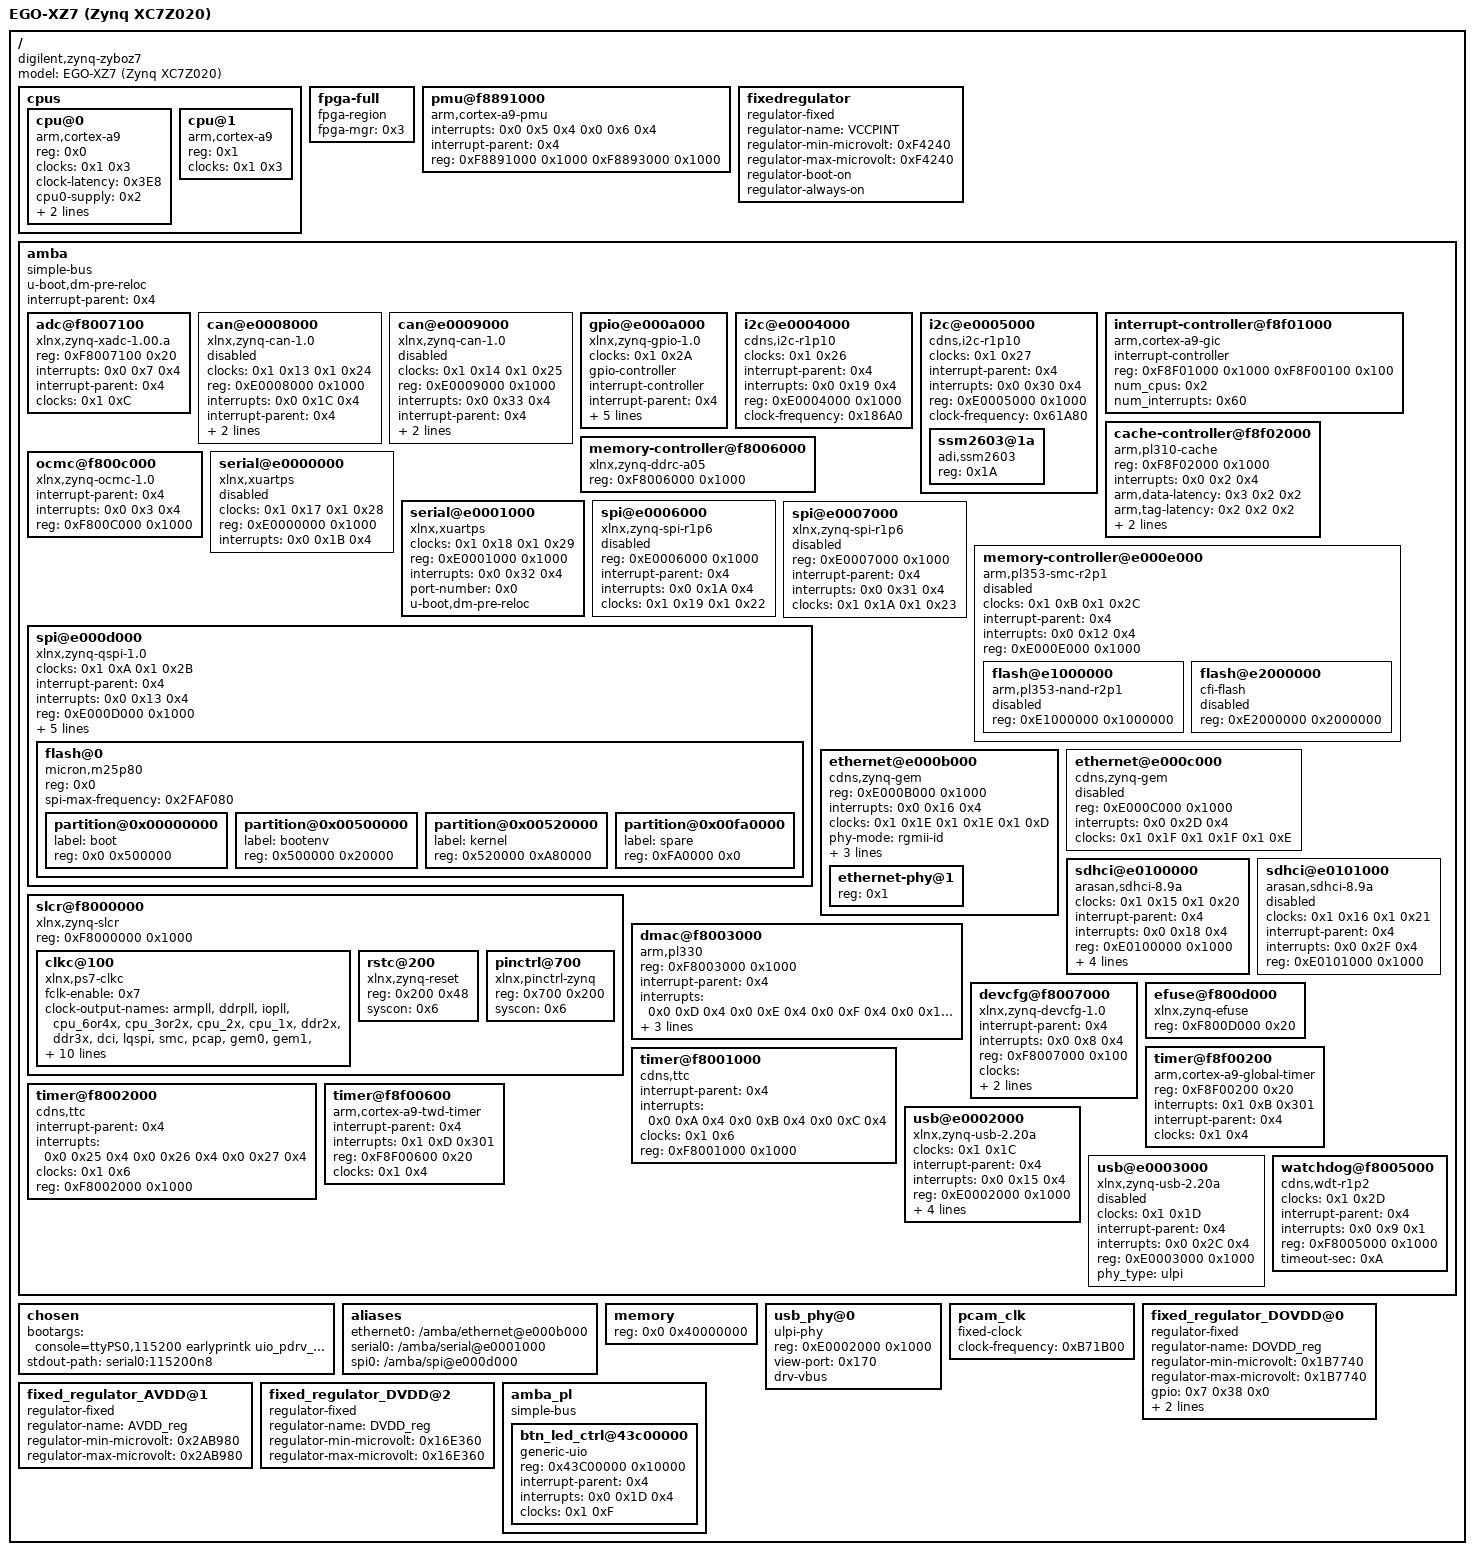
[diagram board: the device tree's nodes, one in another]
/dts-v1/;
// version: 17
// last_comp_version: 16
// boot_cpuid_phys: 0x0

/ {
    #address-cells = <0x1>;
    #size-cells = <0x1>;
    compatible = "digilent,zynq-zyboz7", "xlnx,zynq-7000";
    model = "EGO-XZ7 (Zynq XC7Z020)";
    cpus {
        #address-cells = <0x1>;
        #size-cells = <0x0>;
        cpu@0 {
            compatible = "arm,cortex-a9";
            device_type = "cpu";
            reg = <0x0>;
            clocks = <0x1 0x3>;
            clock-latency = <0x3E8>;
            cpu0-supply = <0x2>;
            operating-points = <0xA2C2A 0xF4240 0x51615 0xF4240>;
        };
        cpu@1 {
            compatible = "arm,cortex-a9";
            device_type = "cpu";
            reg = <0x1>;
            clocks = <0x1 0x3>;
        };
    };
    fpga-full {
        compatible = "fpga-region";
        fpga-mgr = <0x3>;
        #address-cells = <0x1>;
        #size-cells = <0x1>;
        ranges;
    };
    pmu@f8891000 {
        compatible = "arm,cortex-a9-pmu";
        interrupts = <0x0 0x5 0x4 0x0 0x6 0x4>;
        interrupt-parent = <0x4>;
        reg = <0xF8891000 0x1000 0xF8893000 0x1000>;
    };
    fixedregulator {
        compatible = "regulator-fixed";
        regulator-name = "VCCPINT";
        regulator-min-microvolt = <0xF4240>;
        regulator-max-microvolt = <0xF4240>;
        regulator-boot-on;
        regulator-always-on;
        linux,phandle = <0x2>;
        phandle = <0x2>;
    };
    amba {
        u-boot,dm-pre-reloc;
        compatible = "simple-bus";
        #address-cells = <0x1>;
        #size-cells = <0x1>;
        interrupt-parent = <0x4>;
        ranges;
        adc@f8007100 {
            compatible = "xlnx,zynq-xadc-1.00.a";
            reg = <0xF8007100 0x20>;
            interrupts = <0x0 0x7 0x4>;
            interrupt-parent = <0x4>;
            clocks = <0x1 0xC>;
        };
        can@e0008000 {
            compatible = "xlnx,zynq-can-1.0";
            status = "disabled";
            clocks = <0x1 0x13 0x1 0x24>;
            clock-names = "can_clk", "pclk";
            reg = <0xE0008000 0x1000>;
            interrupts = <0x0 0x1C 0x4>;
            interrupt-parent = <0x4>;
            tx-fifo-depth = <0x40>;
            rx-fifo-depth = <0x40>;
        };
        can@e0009000 {
            compatible = "xlnx,zynq-can-1.0";
            status = "disabled";
            clocks = <0x1 0x14 0x1 0x25>;
            clock-names = "can_clk", "pclk";
            reg = <0xE0009000 0x1000>;
            interrupts = <0x0 0x33 0x4>;
            interrupt-parent = <0x4>;
            tx-fifo-depth = <0x40>;
            rx-fifo-depth = <0x40>;
        };
        gpio@e000a000 {
            compatible = "xlnx,zynq-gpio-1.0";
            #gpio-cells = <0x2>;
            clocks = <0x1 0x2A>;
            gpio-controller;
            interrupt-controller;
            #interrupt-cells = <0x2>;
            interrupt-parent = <0x4>;
            interrupts = <0x0 0x14 0x4>;
            reg = <0xE000A000 0x1000>;
            emio-gpio-width = <0x40>;
            gpio-mask-high = <0x0>;
            gpio-mask-low = <0x5600>;
            linux,phandle = <0x7>;
            phandle = <0x7>;
        };
        i2c@e0004000 {
            compatible = "cdns,i2c-r1p10";
            status = "okay";
            clocks = <0x1 0x26>;
            interrupt-parent = <0x4>;
            interrupts = <0x0 0x19 0x4>;
            reg = <0xE0004000 0x1000>;
            #address-cells = <0x1>;
            #size-cells = <0x0>;
            clock-frequency = <0x186A0>;
            linux,phandle = <0x12>;
            phandle = <0x12>;
        };
        i2c@e0005000 {
            compatible = "cdns,i2c-r1p10";
            status = "okay";
            clocks = <0x1 0x27>;
            interrupt-parent = <0x4>;
            interrupts = <0x0 0x30 0x4>;
            reg = <0xE0005000 0x1000>;
            #address-cells = <0x1>;
            #size-cells = <0x0>;
            clock-frequency = <0x61A80>;
            ssm2603@1a {
                #sound-dai-cells = <0x0>;
                compatible = "adi,ssm2603";
                reg = <0x1A>;
                linux,phandle = <0x19>;
                phandle = <0x19>;
            };
        };
        interrupt-controller@f8f01000 {
            compatible = "arm,cortex-a9-gic";
            #interrupt-cells = <0x3>;
            interrupt-controller;
            reg = <0xF8F01000 0x1000 0xF8F00100 0x100>;
            num_cpus = <0x2>;
            num_interrupts = <0x60>;
            linux,phandle = <0x4>;
            phandle = <0x4>;
        };
        cache-controller@f8f02000 {
            compatible = "arm,pl310-cache";
            reg = <0xF8F02000 0x1000>;
            interrupts = <0x0 0x2 0x4>;
            arm,data-latency = <0x3 0x2 0x2>;
            arm,tag-latency = <0x2 0x2 0x2>;
            cache-unified;
            cache-level = <0x2>;
        };
        memory-controller@f8006000 {
            compatible = "xlnx,zynq-ddrc-a05";
            reg = <0xF8006000 0x1000>;
        };
        ocmc@f800c000 {
            compatible = "xlnx,zynq-ocmc-1.0";
            interrupt-parent = <0x4>;
            interrupts = <0x0 0x3 0x4>;
            reg = <0xF800C000 0x1000>;
        };
        serial@e0000000 {
            compatible = "xlnx,xuartps", "cdns,uart-r1p8";
            status = "disabled";
            clocks = <0x1 0x17 0x1 0x28>;
            clock-names = "uart_clk", "pclk";
            reg = <0xE0000000 0x1000>;
            interrupts = <0x0 0x1B 0x4>;
        };
        serial@e0001000 {
            compatible = "xlnx,xuartps", "cdns,uart-r1p8";
            status = "okay";
            clocks = <0x1 0x18 0x1 0x29>;
            clock-names = "uart_clk", "pclk";
            reg = <0xE0001000 0x1000>;
            interrupts = <0x0 0x32 0x4>;
            device_type = "serial";
            port-number = <0x0>;
            u-boot,dm-pre-reloc;
        };
        spi@e0006000 {
            compatible = "xlnx,zynq-spi-r1p6";
            reg = <0xE0006000 0x1000>;
            status = "disabled";
            interrupt-parent = <0x4>;
            interrupts = <0x0 0x1A 0x4>;
            clocks = <0x1 0x19 0x1 0x22>;
            clock-names = "ref_clk", "pclk";
            #address-cells = <0x1>;
            #size-cells = <0x0>;
        };
        spi@e0007000 {
            compatible = "xlnx,zynq-spi-r1p6";
            reg = <0xE0007000 0x1000>;
            status = "disabled";
            interrupt-parent = <0x4>;
            interrupts = <0x0 0x31 0x4>;
            clocks = <0x1 0x1A 0x1 0x23>;
            clock-names = "ref_clk", "pclk";
            #address-cells = <0x1>;
            #size-cells = <0x0>;
        };
        spi@e000d000 {
            clock-names = "ref_clk", "pclk";
            clocks = <0x1 0xA 0x1 0x2B>;
            compatible = "xlnx,zynq-qspi-1.0";
            status = "okay";
            interrupt-parent = <0x4>;
            interrupts = <0x0 0x13 0x4>;
            reg = <0xE000D000 0x1000>;
            #address-cells = <0x1>;
            #size-cells = <0x0>;
            is-dual = <0x0>;
            num-cs = <0x1>;
            spi-rx-bus-width = <0x4>;
            spi-tx-bus-width = <0x4>;
            u-boot,dm-pre-reloc;
            flash@0 {
                compatible = "micron,m25p80", "s25fl128s", "spi-flash";
                reg = <0x0>;
                #address-cells = <0x1>;
                #size-cells = <0x1>;
                spi-max-frequency = <0x2FAF080>;
                partition@0x00000000 {
                    label = "boot";
                    reg = <0x0 0x500000>;
                };
                partition@0x00500000 {
                    label = "bootenv";
                    reg = <0x500000 0x20000>;
                };
                partition@0x00520000 {
                    label = "kernel";
                    reg = <0x520000 0xA80000>;
                };
                partition@0x00fa0000 {
                    label = "spare";
                    reg = <0xFA0000 0x0>;
                };
            };
        };
        memory-controller@e000e000 {
            #address-cells = <0x1>;
            #size-cells = <0x1>;
            status = "disabled";
            clock-names = "memclk", "aclk";
            clocks = <0x1 0xB 0x1 0x2C>;
            compatible = "arm,pl353-smc-r2p1";
            interrupt-parent = <0x4>;
            interrupts = <0x0 0x12 0x4>;
            ranges;
            reg = <0xE000E000 0x1000>;
            flash@e1000000 {
                status = "disabled";
                compatible = "arm,pl353-nand-r2p1";
                reg = <0xE1000000 0x1000000>;
                #address-cells = <0x1>;
                #size-cells = <0x1>;
            };
            flash@e2000000 {
                status = "disabled";
                compatible = "cfi-flash";
                reg = <0xE2000000 0x2000000>;
                #address-cells = <0x1>;
                #size-cells = <0x1>;
            };
        };
        ethernet@e000b000 {
            compatible = "cdns,zynq-gem", "cdns,gem";
            reg = <0xE000B000 0x1000>;
            status = "okay";
            interrupts = <0x0 0x16 0x4>;
            clocks = <0x1 0x1E 0x1 0x1E 0x1 0xD>;
            clock-names = "pclk", "hclk", "tx_clk";
            #address-cells = <0x1>;
            #size-cells = <0x0>;
            phy-mode = "rgmii-id";
            xlnx,ptp-enet-clock = <0x69F6BCB>;
            local-mac-address;
            phy-handle = <0x5>;
            ethernet-phy@1 {
                reg = <0x1>;
                device_type = "ethernet-phy";
                linux,phandle = <0x5>;
                phandle = <0x5>;
            };
        };
        ethernet@e000c000 {
            compatible = "cdns,zynq-gem", "cdns,gem";
            reg = <0xE000C000 0x1000>;
            status = "disabled";
            interrupts = <0x0 0x2D 0x4>;
            clocks = <0x1 0x1F 0x1 0x1F 0x1 0xE>;
            clock-names = "pclk", "hclk", "tx_clk";
            #address-cells = <0x1>;
            #size-cells = <0x0>;
        };
        sdhci@e0100000 {
            compatible = "arasan,sdhci-8.9a";
            status = "okay";
            clock-names = "clk_xin", "clk_ahb";
            clocks = <0x1 0x15 0x1 0x20>;
            interrupt-parent = <0x4>;
            interrupts = <0x0 0x18 0x4>;
            reg = <0xE0100000 0x1000>;
            xlnx,has-cd = <0x1>;
            xlnx,has-power = <0x0>;
            xlnx,has-wp = <0x0>;
            u-boot,dm-pre-reloc;
        };
        sdhci@e0101000 {
            compatible = "arasan,sdhci-8.9a";
            status = "disabled";
            clock-names = "clk_xin", "clk_ahb";
            clocks = <0x1 0x16 0x1 0x21>;
            interrupt-parent = <0x4>;
            interrupts = <0x0 0x2F 0x4>;
            reg = <0xE0101000 0x1000>;
        };
        slcr@f8000000 {
            #address-cells = <0x1>;
            #size-cells = <0x1>;
            compatible = "xlnx,zynq-slcr", "syscon", "simple-mfd";
            reg = <0xF8000000 0x1000>;
            ranges;
            linux,phandle = <0x6>;
            phandle = <0x6>;
            clkc@100 {
                #clock-cells = <0x1>;
                compatible = "xlnx,ps7-clkc";
                fclk-enable = <0x7>;
                clock-output-names = "armpll", "ddrpll", "iopll", "cpu_6or4x", "cpu_3or2x", "cpu_2x", "cpu_1x", "ddr2x", "ddr3x", "dci", "lqspi", "smc", "pcap", "gem0", "gem1", "fclk0", "fclk1", "fclk2", "fclk3", "can0", "can1", "sdio0", "sdio1", "uart0", "uart1", "spi0", "spi1", "dma", "usb0_aper", "usb1_aper", "gem0_aper", "gem1_aper", "sdio0_aper", "sdio1_aper", "spi0_aper", "spi1_aper", "can0_aper", "can1_aper", "i2c0_aper", "i2c1_aper", "uart0_aper", "uart1_aper", "gpio_aper", "lqspi_aper", "smc_aper", "swdt", "dbg_trc", "dbg_apb";
                reg = <0x100 0x100>;
                ps-clk-frequency = <0x1FCA055>;
                linux,phandle = <0x1>;
                phandle = <0x1>;
            };
            rstc@200 {
                compatible = "xlnx,zynq-reset";
                reg = <0x200 0x48>;
                #reset-cells = <0x1>;
                syscon = <0x6>;
            };
            pinctrl@700 {
                compatible = "xlnx,pinctrl-zynq";
                reg = <0x700 0x200>;
                syscon = <0x6>;
            };
        };
        dmac@f8003000 {
            compatible = "arm,pl330", "arm,primecell";
            reg = <0xF8003000 0x1000>;
            interrupt-parent = <0x4>;
            interrupt-names = "abort", "dma0", "dma1", "dma2", "dma3", "dma4", "dma5", "dma6", "dma7";
            interrupts = <0x0 0xD 0x4 0x0 0xE 0x4 0x0 0xF 0x4 0x0 0x10 0x4 0x0 0x11 0x4 0x0 0x28 0x4 0x0 0x29 0x4 0x0 0x2A 0x4 0x0 0x2B 0x4>;
            #dma-cells = <0x1>;
            #dma-channels = <0x8>;
            #dma-requests = <0x4>;
            clocks = <0x1 0x1B>;
            clock-names = "apb_pclk";
            linux,phandle = <0xA>;
            phandle = <0xA>;
        };
        devcfg@f8007000 {
            compatible = "xlnx,zynq-devcfg-1.0";
            interrupt-parent = <0x4>;
            interrupts = <0x0 0x8 0x4>;
            reg = <0xF8007000 0x100>;
            clocks = <0x1 0xC 0x1 0xF 0x1 0x10 0x1 0x11 0x1 0x12>;
            clock-names = "ref_clk", "fclk0", "fclk1", "fclk2", "fclk3";
            syscon = <0x6>;
            linux,phandle = <0x3>;
            phandle = <0x3>;
        };
        efuse@f800d000 {
            compatible = "xlnx,zynq-efuse";
            reg = <0xF800D000 0x20>;
        };
        timer@f8f00200 {
            compatible = "arm,cortex-a9-global-timer";
            reg = <0xF8F00200 0x20>;
            interrupts = <0x1 0xB 0x301>;
            interrupt-parent = <0x4>;
            clocks = <0x1 0x4>;
        };
        timer@f8001000 {
            interrupt-parent = <0x4>;
            interrupts = <0x0 0xA 0x4 0x0 0xB 0x4 0x0 0xC 0x4>;
            compatible = "cdns,ttc";
            clocks = <0x1 0x6>;
            reg = <0xF8001000 0x1000>;
        };
        timer@f8002000 {
            interrupt-parent = <0x4>;
            interrupts = <0x0 0x25 0x4 0x0 0x26 0x4 0x0 0x27 0x4>;
            compatible = "cdns,ttc";
            clocks = <0x1 0x6>;
            reg = <0xF8002000 0x1000>;
        };
        timer@f8f00600 {
            interrupt-parent = <0x4>;
            interrupts = <0x1 0xD 0x301>;
            compatible = "arm,cortex-a9-twd-timer";
            reg = <0xF8F00600 0x20>;
            clocks = <0x1 0x4>;
        };
        usb@e0002000 {
            compatible = "xlnx,zynq-usb-2.20a", "chipidea,usb2";
            status = "okay";
            clocks = <0x1 0x1C>;
            interrupt-parent = <0x4>;
            interrupts = <0x0 0x15 0x4>;
            reg = <0xE0002000 0x1000>;
            phy_type = "ulpi";
            usb-reset = <0x7 0x2E 0x0>;
            dr_mode = "host";
            usb-phy = <0x8>;
        };
        usb@e0003000 {
            compatible = "xlnx,zynq-usb-2.20a", "chipidea,usb2";
            status = "disabled";
            clocks = <0x1 0x1D>;
            interrupt-parent = <0x4>;
            interrupts = <0x0 0x2C 0x4>;
            reg = <0xE0003000 0x1000>;
            phy_type = "ulpi";
        };
        watchdog@f8005000 {
            clocks = <0x1 0x2D>;
            compatible = "cdns,wdt-r1p2";
            interrupt-parent = <0x4>;
            interrupts = <0x0 0x9 0x1>;
            reg = <0xF8005000 0x1000>;
            timeout-sec = <0xA>;
        };
    };
    chosen {
        bootargs = "console=ttyPS0,115200 earlyprintk uio_pdrv_genirq.of_id=generic-uio";
        stdout-path = "serial0:115200n8";
    };
    aliases {
        ethernet0 = "/amba/ethernet@e000b000";
        serial0 = "/amba/serial@e0001000";
        spi0 = "/amba/spi@e000d000";
    };
    memory {
        device_type = "memory";
        reg = <0x0 0x40000000>;
    };
    usb_phy@0 {
        compatible = "ulpi-phy";
        #phy-cells = <0x0>;
        reg = <0xE0002000 0x1000>;
        view-port = <0x170>;
        drv-vbus;
        linux,phandle = <0x8>;
        phandle = <0x8>;
    };
    pcam_clk {
        #clock-cells = <0x0>;
        compatible = "fixed-clock";
        clock-frequency = <0xB71B00>;
        linux,phandle = <0xB>;
        phandle = <0xB>;
    };
    fixed_regulator_DOVDD@0 {
        compatible = "regulator-fixed";
        regulator-name = "DOVDD_reg";
        regulator-min-microvolt = <0x1B7740>;
        regulator-max-microvolt = <0x1B7740>;
        gpio = <0x7 0x38 0x0>;
        startup-delay-us = <0xC350>;
        enable-active-high;
        linux,phandle = <0xC>;
        phandle = <0xC>;
    };
    fixed_regulator_AVDD@1 {
        compatible = "regulator-fixed";
        regulator-name = "AVDD_reg";
        regulator-min-microvolt = <0x2AB980>;
        regulator-max-microvolt = <0x2AB980>;
        linux,phandle = <0xD>;
        phandle = <0xD>;
    };
    fixed_regulator_DVDD@2 {
        compatible = "regulator-fixed";
        regulator-name = "DVDD_reg";
        regulator-min-microvolt = <0x16E360>;
        regulator-max-microvolt = <0x16E360>;
        linux,phandle = <0xE>;
        phandle = <0xE>;
    };
    amba_pl {
        #address-cells = <0x1>;
        #size-cells = <0x1>;
        compatible = "simple-bus";
        ranges;
        btn_led_ctrl@43c00000 {
            compatible = "generic-uio";
            reg = <0x43C00000 0x10000>;
            interrupt-parent = <0x4>;
            interrupts = <0x0 0x1D 0x4>;
            clocks = <0x1 0xF>;
        };
    };
};
